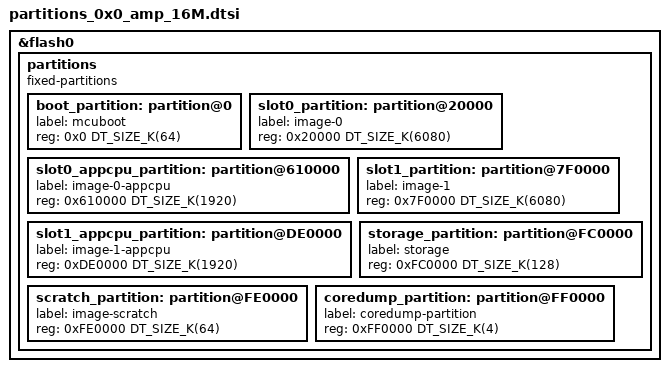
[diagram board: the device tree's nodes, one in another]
/*
 * Copyright (c) 2024 Espressif Systems (Shanghai) Co., Ltd.
 *
 * SPDX-License-Identifier: Apache-2.0
 */

 /* 16MB flash partition table */
&flash0 {
	partitions {
		compatible = "fixed-partitions";
		#address-cells = <1>;
		#size-cells = <1>;

		boot_partition: partition@0 {
			label = "mcuboot";
			reg = <0x0 DT_SIZE_K(64)>;
		};

		slot0_partition: partition@20000 {
			label = "image-0";
			reg = <0x20000 DT_SIZE_K(6080)>;
		};

		slot0_appcpu_partition: partition@610000 {
			label = "image-0-appcpu";
			reg = <0x610000 DT_SIZE_K(1920)>;
		};

		slot1_partition: partition@7F0000 {
			label = "image-1";
			reg = <0x7F0000 DT_SIZE_K(6080)>;
		};

		slot1_appcpu_partition: partition@DE0000 {
			label = "image-1-appcpu";
			reg = <0xDE0000 DT_SIZE_K(1920)>;
		};

		storage_partition: partition@FC0000 {
			label = "storage";
			reg = <0xFC0000 DT_SIZE_K(128)>;
		};

		scratch_partition: partition@FE0000 {
			   label = "image-scratch";
			   reg = <0xFE0000 DT_SIZE_K(64)>;
		};

		coredump_partition: partition@FF0000 {
			label = "coredump-partition";
			reg = <0xFF0000 DT_SIZE_K(4)>;
		};
	};
};
